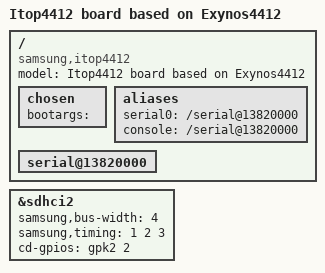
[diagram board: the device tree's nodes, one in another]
// SPDX-License-Identifier: GPL-2.0+
/*
 * Samsung's Exynos4412 based Itop4412 board device tree source
 *
 * Copyright (c) 2014 Samsung Electronics Co., Ltd.
 *		http://www.samsung.com
 */

/dts-v1/;
#include "skeleton.dtsi"
#include "exynos4412.dtsi"

/ {
	model = "Itop4412 board based on Exynos4412";
	compatible = "samsung,itop4412", "samsung,exynos4412";

	chosen {
		bootargs ="";
	};

	aliases {
		serial0 = "/serial@13820000";
		console = "/serial@13820000";
	};

	serial@13820000{
		status = "okay";
	};
};

&sdhci2 {
	samsung,bus-width = <4>;
	samsung,timing = <1 2 3>;
	cd-gpios = <&gpk2 2 0>;
	status = "okay";
};
